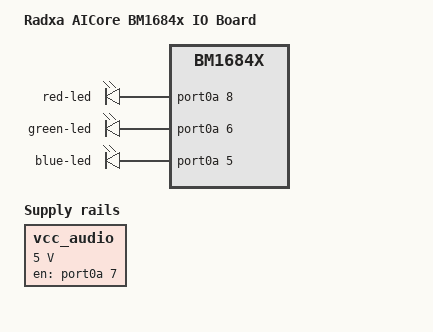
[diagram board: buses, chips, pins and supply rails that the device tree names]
#include "bm1684x_radxa_aicore.dtsi"

/ {
	model = "Radxa AICore BM1684x IO Board";
	/delete-node/ pka@58008000;
	/delete-node/ clp890@50018000;
	info {
		file-name = "bm1684x_radxa_aicore_io.dtb";
	};

	vcc_audio: audio-regulator {
		compatible = "regulator-fixed";
		enable-active-high;
		regulator-always-on;
		regulator-boot-on;
		gpio = <&port0a 7 GPIO_ACTIVE_HIGH>;
		regulator-name = "vcc_audio";
		regulator-min-microvolt = <5000000>;
		regulator-max-microvolt = <5000000>;
	};

	gpio-leds {
		compatible = "gpio-leds";
		pinctrl-names = "default";

		red-led {
			label = "red-led";
			gpios = <&port0a 8 GPIO_ACTIVE_HIGH>;
			linux,default-trigger = "none";
			default-state = "off";
		};

		green-led {
			label = "green-led";
			gpios = <&port0a 6 GPIO_ACTIVE_HIGH>;
			linux,default-trigger = "none";
			default-state = "off";
		};

		blue-led {
			label = "blue-led";
			gpios = <&port0a 5 GPIO_ACTIVE_HIGH>;
			linux,default-trigger = "heartbeat";
			default-state = "on";
		};
	};
};
